# nrf9230_celldsp register map
Vendor: Nordic Semiconductor; Series: nRF92; File version: 1
Registers are 32-bit, read-write, reset 0x0 unless marked. A register's access mark holds for its fields unless they carry their own. Offsets are from the block's base; [hi:lo] are bit positions; {n}, {i} and the like mark numbered series; 'fields as' and 'values as' point back to an identical list.

## LTEFE — LTE Front End
Base 0x4500A000
0x00 TASKS_STARTRX wo — Start receiving rx samples from RF digital
  [0] TASKS_STARTRX
    1=Trigger task
0x04 TASKS_STOPRX wo — Stop receiving rx samples from RF digital
  [0] TASKS_STOPRX
    1=Trigger task
0x08 TASKS_STARTNMEAS wo — Start receiving neighbour measurement rx samples from RF digital
  [0] TASKS_STARTNMEAS
    1=Trigger task
0x0C TASKS_STOPNMEAS wo — Stop receiving neighbour measurement rx samples from RF digital
  [0] TASKS_STOPNMEAS
    1=Trigger task
0x10 TASKS_STARTNMEASTIMED wo — Start receiving TBC timed neighbour measurement rx samples from RF digital
  [0] TASKS_STARTNMEASTIMED
    1=Trigger task
0x14 TASKS_STOPNMEASTIMED wo — Stop receiving TBC timed neighbour measurement rx samples from RF digital
  [0] TASKS_STOPNMEASTIMED
    1=Trigger task
0x18 TASKS_STARTTX wo — Start transmitting tx samples to RF digital
  [0] TASKS_STARTTX
    1=Trigger task
0x1C TASKS_STOPTX wo — Stop transmitting tx samples to RF digital
  [0] TASKS_STOPTX
    1=Trigger task
0x20 TASKS_RESET wo — Reset configuration registers to initial state.
  [0] TASKS_RESET
    1=Trigger task
0x100 EVENTS_RXSAMPLEREADY — Programmable number of rx samples received from RF digital
  [0] EVENTS_RXSAMPLEREADY
    0=NotGenerated (Event not generated); 1=Generated (Event generated)
0x104 EVENTS_RXSADDRREADY — Rx samples written to programmable DTCM buffer address
  [0] EVENTS_RXSADDRREADY
    values as EVENTS_RXSAMPLEREADY.EVENTS_RXSAMPLEREADY
0x108 EVENTS_RX2SADDRREADY — Rx samples written to programmable secondary DTCM buffer address
  [0] EVENTS_RX2SADDRREADY
    values as EVENTS_RXSAMPLEREADY.EVENTS_RXSAMPLEREADY
0x10C EVENTS_NMEASSAMPLEREADY — Programmable number of neighbour measurement samples received from RF digital
  [0] EVENTS_NMEASSAMPLEREADY
    values as EVENTS_RXSAMPLEREADY.EVENTS_RXSAMPLEREADY
0x110 EVENTS_NMEASSADDRREADY — NMeas rx samples written to programmable DTCM buffer address
  [0] EVENTS_NMEASSADDRREADY
    values as EVENTS_RXSAMPLEREADY.EVENTS_RXSAMPLEREADY
0x114 EVENTS_TXSAMPLEREADY — Programmable number of tx samples transferred
  [0] EVENTS_TXSAMPLEREADY
    values as EVENTS_RXSAMPLEREADY.EVENTS_RXSAMPLEREADY
0x118 EVENTS_DMADONE — First DMA transfer from DTCM to LteFE ready
  [0] EVENTS_DMADONE
    values as EVENTS_RXSAMPLEREADY.EVENTS_RXSAMPLEREADY
0x11C EVENTS_RXWATCHDOG — Rx WatchDog event
  [0] EVENTS_RXWATCHDOG
    values as EVENTS_RXSAMPLEREADY.EVENTS_RXSAMPLEREADY
0x120 EVENTS_TXWATCHDOG — Tx WatchDog event
  [0] EVENTS_TXWATCHDOG
    values as EVENTS_RXSAMPLEREADY.EVENTS_RXSAMPLEREADY
0x124 EVENTS_RXOVERFLOW — Rx fifo overflow event
  [0] EVENTS_RXOVERFLOW
    values as EVENTS_RXSAMPLEREADY.EVENTS_RXSAMPLEREADY
0x128 EVENTS_TXUNDERFLOW — Tx fifo underflow event
  [0] EVENTS_TXUNDERFLOW
    values as EVENTS_RXSAMPLEREADY.EVENTS_RXSAMPLEREADY
0x12C EVENTS_NMEASOVERFLOW — NMeas rx fifo overflow event
  [0] EVENTS_NMEASOVERFLOW
    values as EVENTS_RXSAMPLEREADY.EVENTS_RXSAMPLEREADY
0x130 EVENTS_RXRESYNCOVERFLOW — Rx Resync fifo overflow event
  [0] EVENTS_RXRESYNCOVERFLOW
    values as EVENTS_RXSAMPLEREADY.EVENTS_RXSAMPLEREADY
0x134 EVENTS_RX2SAMPLEREADY — Programmable number of rx samples received to secondary buffer from RF digital
  [0] EVENTS_RX2SAMPLEREADY
    values as EVENTS_RXSAMPLEREADY.EVENTS_RXSAMPLEREADY
0x138 EVENTS_NMEAS2SAMPLEREADY — Programmable number of NMeas samples received to secondary buffer from RF digital
  [0] EVENTS_NMEAS2SAMPLEREADY
    values as EVENTS_RXSAMPLEREADY.EVENTS_RXSAMPLEREADY
0x13C EVENTS_NMEAS2SADDRREADY — NMeas rx samples written to programmable secondary DTCM buffer address
  [0] EVENTS_NMEAS2SADDRREADY
    values as EVENTS_RXSAMPLEREADY.EVENTS_RXSAMPLEREADY
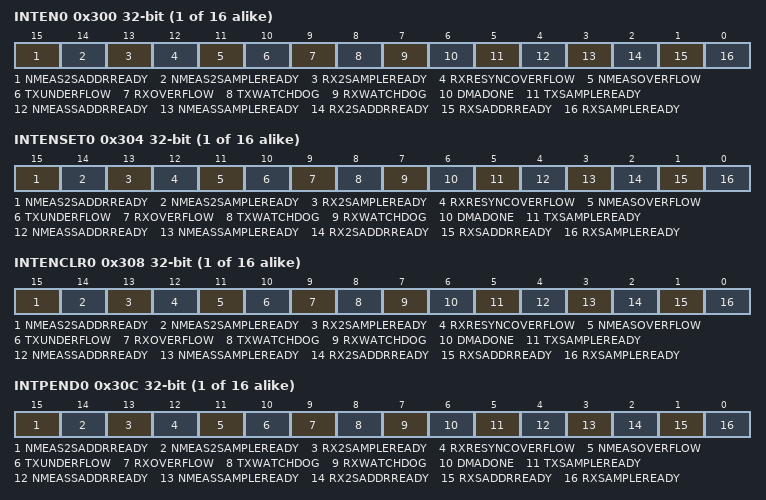
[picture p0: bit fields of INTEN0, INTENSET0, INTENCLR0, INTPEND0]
{0x300+0x10*i} INTEN{i} (i=0..15) — Enable or disable interrupt
  [all] fields
    0=Disabled; 1=Enabled
  [15] NMEAS2SADDRREADY — Enable or disable interrupt for event NMEAS2SADDRREADY
  [14] NMEAS2SAMPLEREADY — Enable or disable interrupt for event NMEAS2SAMPLEREADY
  [13] RX2SAMPLEREADY — Enable or disable interrupt for event RX2SAMPLEREADY
  [12] RXRESYNCOVERFLOW — Enable or disable interrupt for event RXRESYNCOVERFLOW
  [11] NMEASOVERFLOW — Enable or disable interrupt for event NMEASOVERFLOW
  [10] TXUNDERFLOW — Enable or disable interrupt for event TXUNDERFLOW
  [9] RXOVERFLOW — Enable or disable interrupt for event RXOVERFLOW
  [8] TXWATCHDOG — Enable or disable interrupt for event TXWATCHDOG
  [7] RXWATCHDOG — Enable or disable interrupt for event RXWATCHDOG
  [6] DMADONE — Enable or disable interrupt for event DMADONE
  [5] TXSAMPLEREADY — Enable or disable interrupt for event TXSAMPLEREADY
  [4] NMEASSADDRREADY — Enable or disable interrupt for event NMEASSADDRREADY
  [3] NMEASSAMPLEREADY — Enable or disable interrupt for event NMEASSAMPLEREADY
  [2] RX2SADDRREADY — Enable or disable interrupt for event RX2SADDRREADY
  [1] RXSADDRREADY — Enable or disable interrupt for event RXSADDRREADY
  [0] RXSAMPLEREADY — Enable or disable interrupt for event RXSAMPLEREADY
{0x304+0x10*i} INTENSET{i} (i=0..15) — Enable interrupt
  [all] fields
    on read: 0=Disabled (Read: Disabled); 1=Enabled (Read: Enabled) | on write: 1=Set (Enable)
  [15] NMEAS2SADDRREADY — Write '1' to enable interrupt for event NMEAS2SADDRREADY
  [14] NMEAS2SAMPLEREADY — Write '1' to enable interrupt for event NMEAS2SAMPLEREADY
  [13] RX2SAMPLEREADY — Write '1' to enable interrupt for event RX2SAMPLEREADY
  [12] RXRESYNCOVERFLOW — Write '1' to enable interrupt for event RXRESYNCOVERFLOW
  [11] NMEASOVERFLOW — Write '1' to enable interrupt for event NMEASOVERFLOW
  [10] TXUNDERFLOW — Write '1' to enable interrupt for event TXUNDERFLOW
  [9] RXOVERFLOW — Write '1' to enable interrupt for event RXOVERFLOW
  [8] TXWATCHDOG — Write '1' to enable interrupt for event TXWATCHDOG
  [7] RXWATCHDOG — Write '1' to enable interrupt for event RXWATCHDOG
  [6] DMADONE — Write '1' to enable interrupt for event DMADONE
  [5] TXSAMPLEREADY — Write '1' to enable interrupt for event TXSAMPLEREADY
  [4] NMEASSADDRREADY — Write '1' to enable interrupt for event NMEASSADDRREADY
  [3] NMEASSAMPLEREADY — Write '1' to enable interrupt for event NMEASSAMPLEREADY
  [2] RX2SADDRREADY — Write '1' to enable interrupt for event RX2SADDRREADY
  [1] RXSADDRREADY — Write '1' to enable interrupt for event RXSADDRREADY
  [0] RXSAMPLEREADY — Write '1' to enable interrupt for event RXSAMPLEREADY
{0x308+0x10*i} INTENCLR{i} (i=0..15) — Disable interrupt
  [all] fields
    on read: 0=Disabled (Read: Disabled); 1=Enabled (Read: Enabled) | on write: 1=Clear (Disable)
  [15] NMEAS2SADDRREADY — Write '1' to disable interrupt for event NMEAS2SADDRREADY
  [14] NMEAS2SAMPLEREADY — Write '1' to disable interrupt for event NMEAS2SAMPLEREADY
  [13] RX2SAMPLEREADY — Write '1' to disable interrupt for event RX2SAMPLEREADY
  [12] RXRESYNCOVERFLOW — Write '1' to disable interrupt for event RXRESYNCOVERFLOW
  [11] NMEASOVERFLOW — Write '1' to disable interrupt for event NMEASOVERFLOW
  [10] TXUNDERFLOW — Write '1' to disable interrupt for event TXUNDERFLOW
  [9] RXOVERFLOW — Write '1' to disable interrupt for event RXOVERFLOW
  [8] TXWATCHDOG — Write '1' to disable interrupt for event TXWATCHDOG
  [7] RXWATCHDOG — Write '1' to disable interrupt for event RXWATCHDOG
  [6] DMADONE — Write '1' to disable interrupt for event DMADONE
  [5] TXSAMPLEREADY — Write '1' to disable interrupt for event TXSAMPLEREADY
  [4] NMEASSADDRREADY — Write '1' to disable interrupt for event NMEASSADDRREADY
  [3] NMEASSAMPLEREADY — Write '1' to disable interrupt for event NMEASSAMPLEREADY
  [2] RX2SADDRREADY — Write '1' to disable interrupt for event RX2SADDRREADY
  [1] RXSADDRREADY — Write '1' to disable interrupt for event RXSADDRREADY
  [0] RXSAMPLEREADY — Write '1' to disable interrupt for event RXSAMPLEREADY
{0x30C+0x10*i} INTPEND{i} ro (i=0..15) — Pending interrupts
  [all] fields
    on read: 0=NotPending (Read: Not pending); 1=Pending (Read: Pending)
  [15] NMEAS2SADDRREADY — Read pending status of interrupt for event NMEAS2SADDRREADY
  [14] NMEAS2SAMPLEREADY — Read pending status of interrupt for event NMEAS2SAMPLEREADY
  [13] RX2SAMPLEREADY — Read pending status of interrupt for event RX2SAMPLEREADY
  [12] RXRESYNCOVERFLOW — Read pending status of interrupt for event RXRESYNCOVERFLOW
  [11] NMEASOVERFLOW — Read pending status of interrupt for event NMEASOVERFLOW
  [10] TXUNDERFLOW — Read pending status of interrupt for event TXUNDERFLOW
  [9] RXOVERFLOW — Read pending status of interrupt for event RXOVERFLOW
  [8] TXWATCHDOG — Read pending status of interrupt for event TXWATCHDOG
  [7] RXWATCHDOG — Read pending status of interrupt for event RXWATCHDOG
  [6] DMADONE — Read pending status of interrupt for event DMADONE
  [5] TXSAMPLEREADY — Read pending status of interrupt for event TXSAMPLEREADY
  [4] NMEASSADDRREADY — Read pending status of interrupt for event NMEASSADDRREADY
  [3] NMEASSAMPLEREADY — Read pending status of interrupt for event NMEASSAMPLEREADY
  [2] RX2SADDRREADY — Read pending status of interrupt for event RX2SADDRREADY
  [1] RXSADDRREADY — Read pending status of interrupt for event RXSADDRREADY
  [0] RXSAMPLEREADY — Read pending status of interrupt for event RXSAMPLEREADY
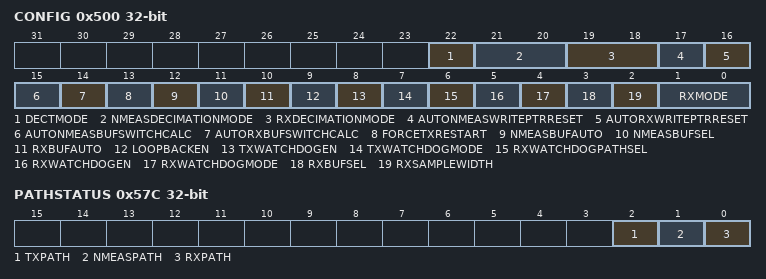
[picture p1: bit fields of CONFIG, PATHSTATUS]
0x500 CONFIG — LTEFE configuration register
  [22] DECTMODE — DECT mode selection. When enabled TBC incremented by 1.
    0=Disabled (DECT mode disabled); 1=Enabled (DECT mode enabled)
  [21:20] NMEASDECIMATIONMODE — NMeas decimation mode selection
    0=NoDecimation; 1=DecimateBy2; 2=DecimateBy4
  [19:18] RXDECIMATIONMODE — Rx decimation mode selection
    0=NoDecimation; 1=DecimateBy2; 2=DecimateBy4
  [17] AUTONMEASWRITEPTRRESET — Automatic NMeas write pointer reset in AHB FSM
    0=Disabled (Autoreset disabled); 1=Enabled (Autoreset enabled)
  [16] AUTORXWRITEPTRRESET — Automatic Rx write pointer reset in AHB FSM
    values as AUTONMEASWRITEPTRRESET
  [15] AUTONMEASBUFSWITCHCALC — Automatic NMeas buffer switchpoint calculation
    0=Disabled (Autocalculation disabled); 1=Enabled (Autocalculation enabled)
  [14] AUTORXBUFSWITCHCALC — Automatic Rx buffer switchpoint calculation
    values as AUTONMEASBUFSWITCHCALC
  [13] FORCETXRESTART — Tx restart mode in continuous transmission
    0=Automatic (LteFe restarts tx automatically); 1=DSPForce (DSP forcing tx restart)
  [12] NMEASBUFAUTO — Automatic NMeas buffer switching mode
    0=Disabled (Automatic mode disabled); 1=Enabled (Automatic mode enabled)
  [11] NMEASBUFSEL — Manual NMeas buffer switching mode. In automatic mode defines also which buffer will be filled first.
    0=Main NMeas buffer selected; 1=Secondary NMeas buffer selected
  [10] RXBUFAUTO — Automatic rx buffer switching mode
    values as NMEASBUFAUTO
  [9] LOOPBACKEN — RX/TX loop-back enable
    0=Disabled (RX/RX loop-back mode disabled); 1=Enabled (RX/TX loop-back mode enabled)
  [8] TXWATCHDOGEN — TX WatchDog enable
    0=Disabled (Tx WatchDog disabled); 1=Enabled (Tx WatchDog enabled)
  [7] TXWATCHDOGMODE — Tx watchdog mode selection
    0=Mode0 (Monitor Tx strobes when tx is ongoing, i.e. first txStrobe has arrived); 1=Mode1 (Monitor first tx strobe after Tx task started)
  [6] RXWATCHDOGPATHSEL — Rx WatchDog path selection
    0=Rx path selected for WatchDog; 1=NMeas path selected for WatchDog
  [5] RXWATCHDOGEN — Rx WatchDog enable
    0=Disabled (Rx WatchDog disabled); 1=Enabled (Rx WatchDog enabled)
  [4] RXWATCHDOGMODE — Rx watchdog mode selection
    0=Mode0 (Monitor Rx strobes when rx is ongoing, i.e. first rxStrobe has arrived.); 1=Mode1 (Monitor first rx strobe after Rx or NMeas tasks started)
  [3] RXBUFSEL — Manual rx buffer switching mode. In automatic mode defines also which buffer will be filled first
    0=Main rx buffer selected; 1=Secondary rx buffer selected
  [2] RXSAMPLEWIDTH — RX IQ sample width selection
    0=12-bit mode: sample in LSB, upper bits sign extended; 1=16-bit mode
  [1:0] RXMODE — RX mode select
    0=Rx1M92sps (Rx mode: 1.92 Msps sample rate); 1=Rx3M84sps (Rx mode 3.84 Msps sample rate, GPS); 2=Rx7M68sps (Rx mode 7.68 Msps sample rate); 3=Rx15M36sps (Rx mode 15.36 Msps sample rate, mRX)
0x504 TBCINITVALUELO — Lower 32 bits of TimeBaseCounter initialization value
  [31:0] TBCINITLO — TBC Initialization
0x508 TBCINITVALUEHI — Higher 32 bits of TimeBaseCounter initialization value
  [31:0] TBCINITHI — TBC Initialization
0x50C TBCRXENDLO — Lower 32 bits of Rx End time
  [31:0] RXENDLO — TBC count to disable RX
0x510 TBCRXENDHI — Higher 32 bits of Rx End time
  [31:0] RXENDHI — TBC count to disable RX
0x514 NMEASSTARTLO — Lower 32 bits of NMeas Start time
  [31:0] NMEASSTARTLO — TBC count to start neighbour measurement
0x518 NMEASSTARTHI — Higher 32 bits of NMeas Start time
  [31:0] NMEASSTARTHI — TBC count to start neighbour measurement
0x51C NMEASSTOPLO — Lower 32 bits of NMeas Stop time
  [31:0] NMEASSTOPLO — TBC count to stop neighbour measurement
0x520 NMEASSTOPHI — Higher 32 bits of NMeas Stop time
  [31:0] NMEASSTOPHI — TBC count to stop neighbour measurement
0x524 RXBUFSWITCHLO — Lower 32 bits of TBC value to switch to another DTCM buffer
  [31:0] RX2SWITCHLO — Switch point to secondary Rx buffer
0x528 RXBUFSWITCHHI — Higher 32 bits of TBC value to switch to another DTCM buffer
  [31:0] RX2SWITCHI — Switch point to secondary Rx buffer
0x52C RXSAMPLEINTTRIG — Rx sample interrupt trigger value. Number of samples received from RF digital.
  [15:0] RXSAMPLEINTTRIG — Rx sample interrupt trigger
0x530 RXSADDRINTTRIG — Rx sample interrupt trigger value. DTCM address where samples written.
  [31:0] RXSADDRINTTRIG — Rx sample interrupt trigger.
0x534 RX2SADDRINTTRIG — Rx 2 sample interrupt trigger value. DTCM address where samples written.
  [31:0] RX2SADDRINTTRIG — Rx 2 sample interrupt trigger
0x538 NMEASSAMPLEINTTRIG — Rx Neighbour measurement sample interrupt trigger value. Number of samples received from RF digital.
  [15:0] NMEASSAMPLEINTTRIG — Rx NMeas sample interrupt trigger
0x53C NMEASSADDRINTTRIG — Rx Neighbour measurement sample interrupt trigger value. DTCM address where samples written.
  [31:0] NMEASSADDRINTTRIG — Rx NMeas sample interrupt trigger
0x540 TXSAMPLEINTTRIG — Tx sample interrupt trigger value. Number of samples transmitted to RF digital.
  [15:0] TXSAMPLEINTTRIG — Tx sample interrupt trigger
0x544 RXDMABASEADDR — Rx write base address to DTCM memory
  [31:0] RXDMABASEADDR — Rx buffer base address
0x548 RXDMABUFFERSIZE — Rx DTCM buffer size
  [31:0] RXDMABUFFERSIZE — Rx buffer size
0x54C RXDMAWRITEPTR — Rx write pointer to DTCM memory
  [31:0] RXDMAWRITEPTR — Rx buffer write pointer
0x550 RX2DMABASEADDR — Rx 2 write base address to DTCM memory
  [31:0] RX2DMABASEADDR — Rx buffer 2 base address
0x554 RX2DMABUFFERSIZE — Rx 2 DTCM buffer size
  [31:0] RX2DMABUFFERSIZE — Rx buffer 2 size
0x558 RX2DMAWRITEPTR — Rx 2 write pointer to DTCM memory
  [31:0] RX2DMAWRITEPTR — Rx buffer 2 write pointer
0x55C NMEASDMABASEADDR — Neighbour measurement write base address to DTCM memory
  [31:0] NMEASDMABASEADDR — NMeas buffer base address
0x560 NMEASDMABUFFERSIZE — Neighbour measurement DTCM buffer size
  [31:0] NMEASDMABUFFERSIZE — NMeas buffer size
0x564 NMEASDMAWRITEPTR — Neighbour measurement write pointer to DTCM memory
  [31:0] NMEASDMAWRITEPTR — NMeas buffer write pointer
0x568 TXDMABASEADDR — Tx write base address to DTCM memory
  [31:0] TXDMABASEADDR — Tx buffer base address
0x56C TXDMABUFFERSIZE — Tx DTCM buffer size
  [31:0] TXDMABUFFERSIZE — Tx buffer size
0x570 TXDMAREADPTR — Tx read pointer from DTCM memory
  [31:0] TXDMAREADPTR — Tx buffer read pointer
0x574 RXWATCHDOGTRIG — Max value of rx WatchDog counter (in 80MHz clock cycles) to monitor rx sample strobes from RF digital
  [15:0] RXWATCHDOGTRIG — Max value of rx WatchDog counter
0x578 TXWATCHDOGTRIG — Max value of tx WatchDog counter (in 80MHz clock cycles) to monitor tx sample strobes from RF digital
  [15:0] TXWATCHDOGTRIG — Max value of tx WatchDog counter
0x57C PATHSTATUS ro
  [2] TXPATH — Tx path status
    0=TaskInactive (Tx task not activated); 1=TaskActive (Tx task ongoing)
  [1] NMEASPATH — Rx measurement path status
    0=TaskInactive (Rx meas task not activated); 1=TaskActive (Rx meas task ongoing)
  [0] RXPATH — RX path status
    0=TaskInactive (Rx task not activated); 1=TaskActive (Rx task ongoing)
0x580 RX2SAMPLEINTTRIG — Rx secondary buffer sample interrupt trigger value. Number of samples received from RF digital.
  [15:0] RX2SAMPLEINTTRIG — Rx 2 sample interrupt trigger
0x584 NMEAS2SAMPLEINTTRIG — NMeas secondary buffer sample interrupt trigger value. Number of samples received from RF digital.
  [15:0] NMEAS2SAMPLEINTTRIG — NMeas 2 sample interrupt trigger
0x588 NMEAS2SADDRINTTRIG — NMeas secondary buffer sample interrupt trigger value. DTCM address where samples written.
  [31:0] NMEAS2SADDRINTTRIG — NMeas 2 sample interrupt trigger
0x58C NMEAS2DMABASEADDR — NMeas 2 write base address to DTCM memory
  [31:0] NMEAS2DMABASEADDR — NMeas buffer 2 base address
0x590 NMEAS2DMABUFFERSIZE — NMeas 2 DTCM buffer size
  [31:0] NMEAS2DMABUFFERSIZE — NMeas buffer 2 size
0x594 NMEAS2DMAWRITEPTR — NMeas 2 write pointer to DTCM memory
  [31:0] NMEAS2DMAWRITEPTR — NMeas buffer 2 write pointer
0x598 NMEASBUFSWITCHLO — Lower 32 bits of TBC value to switch to another DTCM buffer
  [31:0] NMEAS2SWITCHLO — Switch point to secondary NMeas buffer
0x59C NMEASBUFSWITCHHI — Higher 32 bits of TBC value to switch to another DTCM buffer
  [31:0] NMEAS2SWITCHI — Switch point to secondary NMeas buffer
0x5A0 TXIQSAMPLECOUNT — Number of Tx IQ samples in one tx slot
  [15:0] TXIQSAMPLECNT — Tx IQ sample count in one tx slot
0x5A4 RXSAMPLECOUNTER ro — Rx sample counter value
  [15:0] RXSAMPLECNTR
0x5A8 NMEASSAMPLECOUNTER ro — NMeas sample counter value
  [15:0] NMEASSAMPLECNTR
0x5AC TXSAMPLECOUNTER ro — Tx sample counter value
  [15:0] TXSAMPLECNTR
0x5B0 RXSLOTSIZELO — Lower 32 bits of Rx slot size in automatic buffer switching
  [31:0] RXSLOTLO — Rx slot size
0x5B4 RXSLOTSIZEHI — Higher 32 bits of Rx slot size in automatic buffer switching
  [31:0] RXSLOTHI — Rx slot size
0x5B8 NMEASSLOTSIZELO — Lower 32 bits of NMeas slot size in automatic buffer switching
  [31:0] NMEASSLOTLO — NMeas slot size
0x5BC NMEASSLOTSIZEHI — Higher 32 bits of NMeas slot size in automatic buffer switching
  [31:0] NMEASSLOTHI — NMeas slot size
0x5C0 RXSTARTLO — Lower 32 bits of Rx start time in timed rx mode
  [31:0] RXSTARTLO — TBC count to start Rx
0x5C4 RXSTARTHI — Higher 32 bits of Rx start time in timed rx mode
  [31:0] RXSTARTHI — TBC count to start Rx
0x5C8 RXSTOPLO — Lower 32 bits of Rx stop time in timed rx mode
  [31:0] RXSTOPLO — TBC count to stop Rx
0x5CC RXSTOPHI — Higher 32 bits of Rx stop time in timed rx mode
  [31:0] RXSTOPHI — TBC count to stop Rx
0x5D0 POSTSHIFT4RNDPLUS reset 0x8 — Rounding constant for 12 bit output format (positive)
  [31:0] POSTSHIFT4RNDPLUS — Rounding constant for 12 bit output format
0x5D4 POSTSHIFT4RNDMINUS reset 0x7 — Rounding constant for 12 bit output format (negative)
  [31:0] POSTSHIFT4RNDMINUS — Rounding constant for 12 bit output format
0x5D8 POSTSHIFT8RNDPLUS reset 0x80 — Rounding constant for 8 bit output format (positive)
  [31:0] POSTSHIFT8RNDPLUS — Rounding constant for 8 bit output format
0x5DC POSTSHIFT8RNDMINUS reset 0x7F — Rounding constant for 8 bit output format (negative)
  [31:0] POSTSHIFT8RNDMINUS — Rounding constant for 8 bit output format
0x5E0 DECTSTARTLO — Lower 32 bits of DectSync start time
  [31:0] DECTSTARTLO — TBC count to start DectSync
0x5E4 DECTSTARTHI — Higher 32 bits of DectSync start time
  [31:0] DECTSTARTHI — TBC count to start DectSync
0x5E8 DECTSTOPLO — Lower 32 bits of DectSync stop time
  [31:0] DECTSTOPLO — TBC count to stop DectSync
0x5EC DECTSTOPHI — Higher 32 bits of DectSync stop time
  [31:0] DECTSTOPHI — TBC count to stop DectSync
0x5F0 DECTSYNCSAMPLECNTR ro — Number of transferred samples in DectSync mode
  [31:0] DECTSYNCSAMPLECNTR — DectSync sample counter value
0x5F4 RXMAINSAMPLECNTR ro — Total number of transferred Rx samples
0x5F8 NMEASMAINSAMPLECNTR ro — Total number of transferred NMeas samples
0x5FC RXOVERFLOWSAMPLES ro — Number of overflow samples in Rx path
0x600 NMEASOVERFLOWSAMPLES ro — Number of overflow samples in NMeas path

## Notices in the file
Copyright (c) 2010 - 2024, Nordic Semiconductor ASA
All rights reserved.
Redistribution and use in source and binary forms, with or without modification,
are permitted provided that the following conditions are met:
1. Redistributions of source code must retain the above copyright notice, this
list of conditions and the following disclaimer.
2. Redistributions in binary form, except as embedded into a Nordic
Semiconductor ASA integrated circuit in a product or a software update for
such product, must reproduce the above copyright notice, this list of
conditions and the following disclaimer in the documentation and/or other
materials provided with the distribution.
3. Neither the name of Nordic Semiconductor ASA nor the names of its
contributors may be used to endorse or promote products derived from this
software without specific prior written permission.
4. This software, with or without modification, must only be used with a
Nordic Semiconductor ASA integrated circuit.
5. Any software provided in binary form under this license must not be reverse
engineered, decompiled, modified and/or disassembled.
THIS SOFTWARE IS PROVIDED BY NORDIC SEMICONDUCTOR ASA "AS IS" AND ANY EXPRESS
OR IMPLIED WARRANTIES, INCLUDING, BUT NOT LIMITED TO, THE IMPLIED WARRANTIES
OF MERCHANTABILITY, NONINFRINGEMENT, AND FITNESS FOR A PARTICULAR PURPOSE ARE
DISCLAIMED. IN NO EVENT SHALL NORDIC SEMICONDUCTOR ASA OR CONTRIBUTORS BE
LIABLE FOR ANY DIRECT, INDIRECT, INCIDENTAL, SPECIAL, EXEMPLARY, OR
CONSEQUENTIAL DAMAGES (INCLUDING, BUT NOT LIMITED TO, PROCUREMENT OF SUBSTITUTE
GOODS OR SERVICES; LOSS OF USE, DATA, OR PROFITS; OR BUSINESS INTERRUPTION)
HOWEVER CAUSED AND ON ANY THEORY OF LIABILITY, WHETHER IN CONTRACT, STRICT
LIABILITY, OR TORT (INCLUDING NEGLIGENCE OR OTHERWISE) ARISING IN ANY WAY OUT
OF THE USE OF THIS SOFTWARE, EVEN IF ADVISED OF THE POSSIBILITY OF SUCH DAMAGE.
